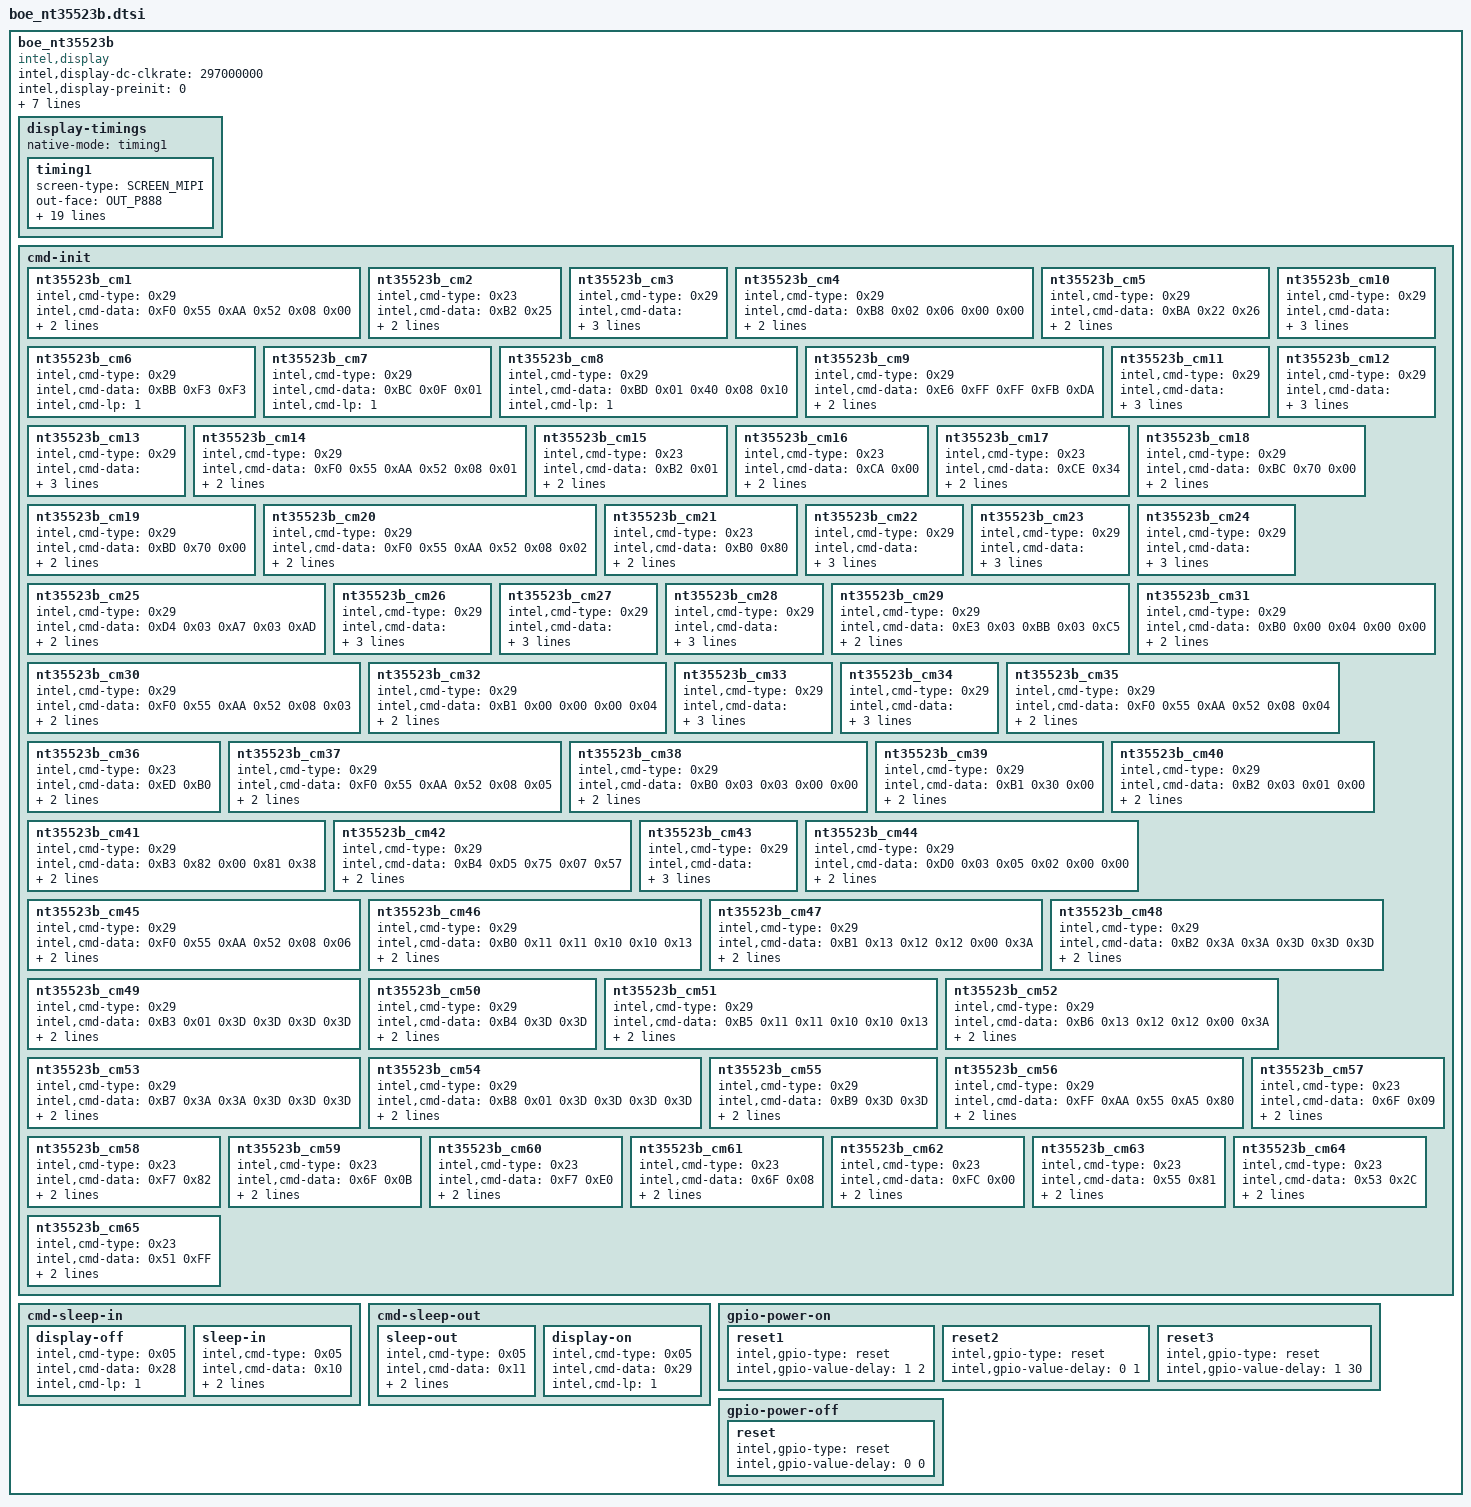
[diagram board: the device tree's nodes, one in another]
/*
 * definition at "include/dt-bindings/sofiafb/sofia_fb.h"
 */
boe_nt35523b {
	compatible = "intel,display";
	intel,display-dc-clkrate = <297000000>;
	intel,display-preinit = <0>;
	intel,display-ramless = <1>;
	intel,display-fps = <60>;
	intel,display-vid-mode = "pulses";
	intel,display-vid-id = <0>;
	intel,display-if-nblanes = <4>;
	intel,display-eot = <0>;
	intel,display-gate = <0>;

        display-timings {
                native-mode = <&timing1>;
                timing1: timing1 {
                        screen-type = <SCREEN_MIPI>;
                        out-face    = <OUT_P888>;
                        color-mode = <COLOR_RGB>;
                        clock-frequency = <71098800>;
                        hactive = <800>;
                        vactive = <1280>;
                        hback-porch = <8>;
                        hfront-porch = <43>;
                        vback-porch = <14>;
                        vfront-porch = <14>;
                        hsync-len = <44>;
                        vsync-len = <4>;
                        hsync-active = <0>;
                        vsync-active = <0>;
                        de-active = <0>;
                        pixelclk-active = <0>;
                        swap-rb = <0>;
                        swap-rg = <0>;
                        swap-gb = <0>;
			width = <95>;
			height = <152>;
                };
        };
	cmd-init{	
			nt35523b_cm1 {
				intel,cmd-type = <0x29>;
				intel,cmd-data = <0xF0 0x55 0xAA 0x52 0x08 0x00>;
				intel,cmd-lp = <1>;
                              intel,cmd-udelay = <20>;
			};
			nt35523b_cm2 {
				intel,cmd-type = <0x23>;
				intel,cmd-data = <0xB2 0x25>;
				intel,cmd-lp = <1>;
                               intel,cmd-udelay = <20>;
			};			
      nt35523b_cm3 {
      intel,cmd-type = <0x29>;
      intel,cmd-data = <0xEF 0x00 0x07 0xFF 0xFF 0x40 0x40>;
      intel,cmd-lp = <1>;
                              intel,cmd-udelay = <20>;
      };
      
			nt35523b_cm4 {
				intel,cmd-type = <0x29>;
				intel,cmd-data = <0xB8 0x02 0x06 0x00 0x00>;
				intel,cmd-lp = <1>;
                                intel,cmd-udelay = <20>;
			};
			nt35523b_cm5 {
				intel,cmd-type = <0x29>;
				intel,cmd-data = <0xBA 0x22 0x26>;
				intel,cmd-lp = <1>;
                                intel,cmd-udelay = <20>;
			};
      nt35523b_cm6 {
      intel,cmd-type = <0x29>;
      intel,cmd-data = <0xBB 0xF3 0xF3>;
                                intel,cmd-lp = <1>;
			};
      nt35523b_cm7 {
      intel,cmd-type = <0x29>;
      intel,cmd-data = <0xBC 0x0F 0x01>;
                                intel,cmd-lp = <1>;
			};
      nt35523b_cm8 {
      intel,cmd-type = <0x29>;
      intel,cmd-data = <0xBD 0x01 0x40 0x08 0x10>;
                                intel,cmd-lp = <1>;
			};						
			nt35523b_cm9 {
				intel,cmd-type = <0x29>;
				intel,cmd-data = <0xE6 0xFF 0xFF 0xFB 0xDA>;
				intel,cmd-lp = <1>;
                                intel,cmd-udelay = <20>;
			};
			nt35523b_cm10 {
				intel,cmd-type = <0x29>;
				intel,cmd-data = <0xCC 0x11 0x11 0x11 0x00 0x00 0x00>;
				intel,cmd-lp = <1>;
                                intel,cmd-udelay = <20>;
			};
			nt35523b_cm11 {
				intel,cmd-type = <0x29>;
				intel,cmd-data = <0xCE 0x10 0x10 0x10 0x10 0x10 0x10 0x10 0x10 0x10 0x10 0x10 0x10>;
				intel,cmd-lp = <1>;
                                intel,cmd-udelay = <20>;
			};
			nt35523b_cm12 {
				intel,cmd-type = <0x29>;
				intel,cmd-data = <0xD7 0x09 0x09 0x09 0x00 0x01 0x00 0x00 0x00 0x01 0x00 0x00 0x00>;
				intel,cmd-lp = <1>;
                                intel,cmd-udelay = <20>;
			};
			nt35523b_cm13 {
				intel,cmd-type = <0x29>;
				intel,cmd-data = <0xD8 0x00 0x00 0x00 0x09 0x09 0x09 0x00 0x00 0x00 0x00 0x09 0x09>;
				intel,cmd-lp = <1>;
                                intel,cmd-udelay = <20>;
			};	
			nt35523b_cm14 {
				intel,cmd-type = <0x29>;
				intel,cmd-data = <0xF0 0x55 0xAA 0x52 0x08 0x01>;
				intel,cmd-lp = <1>;
                                intel,cmd-udelay = <20>;
			};
			nt35523b_cm15 {
				intel,cmd-type = <0x23>;
				intel,cmd-data = <0xB2 0x01>;
				intel,cmd-lp = <1>;
                                intel,cmd-udelay = <20>;
			};
			nt35523b_cm16 {
				intel,cmd-type = <0x23>;
				intel,cmd-data = <0xCA 0x00>;
				intel,cmd-lp = <1>;
                                intel,cmd-udelay = <20>;
			};
			nt35523b_cm17 {
				intel,cmd-type = <0x23>;
				intel,cmd-data = <0xCE 0x34>;
				intel,cmd-lp = <1>;
                                intel,cmd-udelay = <20>;
			};
			nt35523b_cm18 {
				intel,cmd-type = <0x29>;
				intel,cmd-data = <0xBC 0x70 0x00>;
				intel,cmd-lp = <1>;
                                intel,cmd-udelay = <20>;
			};
			nt35523b_cm19 {
				intel,cmd-type = <0x29>;
				intel,cmd-data = <0xBD 0x70 0x00>;
				intel,cmd-lp = <1>;
                                intel,cmd-udelay = <20>;
			};
			nt35523b_cm20 {
				intel,cmd-type = <0x29>;
				intel,cmd-data = <0xF0 0x55 0xAA 0x52 0x08 0x02>;
				intel,cmd-lp = <1>;
                                intel,cmd-udelay = <20>;
			};
			nt35523b_cm21 {
				intel,cmd-type = <0x23>;
				intel,cmd-data = <0xB0 0x80>;
				intel,cmd-lp = <1>;
                                intel,cmd-udelay = <20>;
			};
			nt35523b_cm22 {
				intel,cmd-type = <0x29>;
				intel,cmd-data = <0xD1 0x00 0x24 0x00 0x32 0x00 0x56 0x00 0x6B 0x00 0x89 0x00 0xAA 0x00 0xC7 0x00 0xF3>;
				intel,cmd-lp = <1>;
                                intel,cmd-udelay = <20>;
			};
			nt35523b_cm23 {
				intel,cmd-type = <0x29>;
				intel,cmd-data = <0xD2 0x01 0x18 0x01 0x52 0x01 0x82 0x01 0xC9 0x02 0x05 0x02 0x07 0x02 0x3D 0x02 0x77>;
				intel,cmd-lp = <1>;
                                intel,cmd-udelay = <20>;
			};
			nt35523b_cm24 {
				intel,cmd-type = <0x29>;
				intel,cmd-data = <0xD3 0x02 0x9C 0x02 0xCF 0x02 0xF2 0x03 0x1F 0x03 0x3C 0x03 0x60 0x03 0x75 0x03 0x8E>;
				intel,cmd-lp = <1>;
                                intel,cmd-udelay = <20>;
			};
			nt35523b_cm25 {
				intel,cmd-type = <0x29>;
				intel,cmd-data = <0xD4 0x03 0xA7 0x03 0xAD>;
				intel,cmd-lp = <1>;
                                intel,cmd-udelay = <20>;
			};

			nt35523b_cm26 {
				intel,cmd-type = <0x29>;
				intel,cmd-data = <0xE0 0x00 0x0A 0x00 0x1E 0x00 0x46 0x00 0x5F 0x00 0x7F 0x00 0xA2 0x00 0xC1 0x00 0xEF>;
				intel,cmd-lp = <1>;
                                intel,cmd-udelay = <20>;
			};
			nt35523b_cm27 {
				intel,cmd-type = <0x29>;
				intel,cmd-data = <0xE1 0x01 0x14 0x01 0x50 0x01 0x80 0x01 0xC9 0x02 0x05 0x02 0x07 0x02 0x3D 0x02 0x79>;
				intel,cmd-lp = <1>;
                                intel,cmd-udelay = <20>;
			};
			nt35523b_cm28 {
				intel,cmd-type = <0x29>;
				intel,cmd-data = <0xE2 0x02 0x9E 0x02 0xD3 0x02 0xF6 0x03 0x25 0x03 0x44 0x03 0x6A 0x03 0x81 0x03 0x9E>;
				intel,cmd-lp = <1>;
                                intel,cmd-udelay = <20>;
			};
			nt35523b_cm29 {
				intel,cmd-type = <0x29>;
				intel,cmd-data = <0xE3 0x03 0xBB 0x03 0xC5>;
				intel,cmd-lp = <1>;
                                intel,cmd-udelay = <20>;
			};			
			
			nt35523b_cm30 {
				intel,cmd-type = <0x29>;
				intel,cmd-data = <0xF0 0x55 0xAA 0x52 0x08 0x03>;
				intel,cmd-lp = <1>;
                                intel,cmd-udelay = <20>;
			};
			nt35523b_cm31 {
				intel,cmd-type = <0x29>;
				intel,cmd-data = <0xB0 0x00 0x04 0x00 0x00>;
				intel,cmd-lp = <1>;
                                intel,cmd-udelay = <20>;
			};
			nt35523b_cm32 {
        intel,cmd-type = <0x29>;
        intel,cmd-data = <0xB1 0x00 0x00 0x00 0x04>;
        intel,cmd-lp = <1>;
        intel,cmd-udelay = <20>;
                        };
			nt35523b_cm33 {
				intel,cmd-type = <0x29>;
				intel,cmd-data = <0xB2 0x00 0x00 0x04 0x02 0x00 0xF5 0x42>;
				intel,cmd-lp = <1>;
                                intel,cmd-udelay = <20>;
			};
			nt35523b_cm34 {
				intel,cmd-type = <0x29>;
				intel,cmd-data = <0xBA 0x83 0x01 0x00 0x02 0x00 0xF5 0x42>;
				intel,cmd-lp = <1>;
                                intel,cmd-udelay = <20>;
			};
      nt35523b_cm35 {
        intel,cmd-type = <0x29>;
        intel,cmd-data = <0xF0 0x55 0xAA 0x52 0x08 0x04>;
        intel,cmd-lp = <1>;
                                intel,cmd-udelay = <20>;
      };   
      nt35523b_cm36 {
        intel,cmd-type = <0x23>;
        intel,cmd-data = <0xED 0xB0>;
        intel,cmd-lp = <1>;
                                intel,cmd-udelay = <20>;
      };
        
      nt35523b_cm37 {
        intel,cmd-type = <0x29>;
        intel,cmd-data = <0xF0 0x55 0xAA 0x52 0x08 0x05>;
        intel,cmd-lp = <1>;
                                intel,cmd-udelay = <20>;
      };   
      nt35523b_cm38 {
        intel,cmd-type = <0x29>;
        intel,cmd-data = <0xB0 0x03 0x03 0x00 0x00>;
        intel,cmd-lp = <1>;
                                intel,cmd-udelay = <20>;
      };     
      nt35523b_cm39 {
        intel,cmd-type = <0x29>;
        intel,cmd-data = <0xB1 0x30 0x00>;
        intel,cmd-lp = <1>;
                                intel,cmd-udelay = <20>;
      };   
      nt35523b_cm40 {
        intel,cmd-type = <0x29>;
        intel,cmd-data = <0xB2 0x03 0x01 0x00>;
        intel,cmd-lp = <1>;
                                intel,cmd-udelay = <20>;
      };   
      nt35523b_cm41 {
        intel,cmd-type = <0x29>;
        intel,cmd-data = <0xB3 0x82 0x00 0x81 0x38>;
        intel,cmd-lp = <1>;
                                intel,cmd-udelay = <20>;
      };   
      nt35523b_cm42 {
        intel,cmd-type = <0x29>;
        intel,cmd-data = <0xB4 0xD5 0x75 0x07 0x57>;
        intel,cmd-lp = <1>;
                                intel,cmd-udelay = <20>;
      };                
      nt35523b_cm43 {
        intel,cmd-type = <0x29>;
        intel,cmd-data = <0xB6 0x01 0x00 0xD5 0x71 0x07 0x57>;
        intel,cmd-lp = <1>;
                                intel,cmd-udelay = <20>;
      };   
      nt35523b_cm44 {
        intel,cmd-type = <0x29>;
        intel,cmd-data = <0xD0 0x03 0x05 0x02 0x00 0x00>;
        intel,cmd-lp = <1>;
                                intel,cmd-udelay = <20>;
      };          
			nt35523b_cm45 {
				intel,cmd-type = <0x29>;
				intel,cmd-data = <0xF0 0x55 0xAA 0x52 0x08 0x06>;
				intel,cmd-lp = <1>;
                                intel,cmd-udelay = <20>;
			};
			nt35523b_cm46 {
				intel,cmd-type = <0x29>;
				intel,cmd-data = <0xB0 0x11 0x11 0x10 0x10 0x13>;
				intel,cmd-lp = <1>;
                                intel,cmd-udelay = <20>;
			};
			nt35523b_cm47 {
				intel,cmd-type = <0x29>;
				intel,cmd-data = <0xB1 0x13 0x12 0x12 0x00 0x3A>;
				intel,cmd-lp = <1>;
                                intel,cmd-udelay = <20>;
			};
			nt35523b_cm48 {
				intel,cmd-type = <0x29>;
				intel,cmd-data = <0xB2 0x3A 0x3A 0x3D 0x3D 0x3D>;
				intel,cmd-lp = <1>;
                                intel,cmd-udelay = <20>;
			};
			nt35523b_cm49 {
				intel,cmd-type = <0x29>;
				intel,cmd-data = <0xB3 0x01 0x3D 0x3D 0x3D 0x3D>;
				intel,cmd-lp = <1>;
                                intel,cmd-udelay = <20>;
			};
			nt35523b_cm50 {
				intel,cmd-type = <0x29>;
				intel,cmd-data = <0xB4 0x3D 0x3D>;
				intel,cmd-lp = <1>;
                                intel,cmd-udelay = <20>;
			};
			nt35523b_cm51 {
				intel,cmd-type = <0x29>;
				intel,cmd-data = <0xB5 0x11 0x11 0x10 0x10 0x13>;
				intel,cmd-lp = <1>;
                                intel,cmd-udelay = <20>;
			};

			nt35523b_cm52 {
				intel,cmd-type = <0x29>;
				intel,cmd-data = <0xB6 0x13 0x12 0x12 0x00 0x3A>;
				intel,cmd-lp = <1>;
                                intel,cmd-udelay = <20>;
			};
			nt35523b_cm53 {
				intel,cmd-type = <0x29>;
				intel,cmd-data = <0xB7 0x3A 0x3A 0x3D 0x3D 0x3D>;
				intel,cmd-lp = <1>;
                                intel,cmd-udelay = <20>;
			};
			nt35523b_cm54 {
				intel,cmd-type = <0x29>;
				intel,cmd-data = <0xB8 0x01 0x3D 0x3D 0x3D 0x3D>;
				intel,cmd-lp = <1>;
                                intel,cmd-udelay = <20>;
			};
			nt35523b_cm55 {
				intel,cmd-type = <0x29>;
				intel,cmd-data = <0xB9 0x3D 0x3D>;
				intel,cmd-lp = <1>;
                                intel,cmd-udelay = <20>;
			};			
			nt35523b_cm56 {
				intel,cmd-type = <0x29>;
				intel,cmd-data = <0xFF 0xAA 0x55 0xA5 0x80>;
				intel,cmd-lp = <1>;
                                intel,cmd-udelay = <20>;
			};
			nt35523b_cm57 {
				intel,cmd-type = <0x23>;
				intel,cmd-data = <0x6F 0x09>;
				intel,cmd-lp = <1>;
                                intel,cmd-udelay = <20>;
			};
			nt35523b_cm58 {
				intel,cmd-type = <0x23>;
				intel,cmd-data = <0xF7 0x82>;
				intel,cmd-lp = <1>;
                                intel,cmd-udelay = <20>;
			};
			nt35523b_cm59 {
				intel,cmd-type = <0x23>;
				intel,cmd-data = <0x6F 0x0B>;
				intel,cmd-lp = <1>;
                                intel,cmd-udelay = <20>;
			};

			nt35523b_cm60 {
				intel,cmd-type = <0x23>;
				intel,cmd-data = <0xF7 0xE0>;
				intel,cmd-lp = <1>;
                                intel,cmd-udelay = <20>;
			};						
			nt35523b_cm61 {
				intel,cmd-type = <0x23>;
				intel,cmd-data = <0x6F 0x08>;
				intel,cmd-lp = <1>;
                                intel,cmd-udelay = <20>;
			};

			nt35523b_cm62 {
				intel,cmd-type = <0x23>;
				intel,cmd-data = <0xFC 0x00>;
				intel,cmd-lp = <1>;
                                intel,cmd-udelay = <20>;
			};			
			nt35523b_cm63 {
				intel,cmd-type = <0x23>;
				intel,cmd-data = <0x55 0x81>;
				intel,cmd-lp = <1>;
                                intel,cmd-udelay = <20>;
			};
			nt35523b_cm64 {
				intel,cmd-type = <0x23>;
				intel,cmd-data = <0x53 0x2C>;
				intel,cmd-lp = <1>;
                                intel,cmd-udelay = <20>;
			};
			nt35523b_cm65 {
				intel,cmd-type = <0x23>;
				intel,cmd-data = <0x51 0xFF>;
				intel,cmd-lp = <1>;
                                intel,cmd-udelay = <20>;
			};
	};

	cmd-sleep-in {
		display-off{
			intel,cmd-type = <0x05>;
			intel,cmd-data = <0x28>;
			intel,cmd-lp = <1>;
		};
		sleep-in{
			intel,cmd-type = <0x05>;
			intel,cmd-data = <0x10>;
			intel,cmd-delay = <20>;
			intel,cmd-lp = <1>;
		};
	};

	cmd-sleep-out {
		sleep-out{
			intel,cmd-type = <0x05>;
			intel,cmd-data = <0x11>;
			intel,cmd-delay = <120>;
			intel,cmd-lp = <1>;
		};
		display-on{
			intel,cmd-type = <0x05>;
			intel,cmd-data = <0x29>;
			intel,cmd-lp = <1>;
		};
	};

       gpio-power-on {
               reset1 {
                       intel,gpio-type = "reset";
                       intel,gpio-value-delay = <1 2>;
               };
               reset2 {
                       intel,gpio-type = "reset";
                       intel,gpio-value-delay = <0 1>;
               };
               reset3 {
                       intel,gpio-type = "reset";
                       intel,gpio-value-delay = <1 30>;
               };
       };

       gpio-power-off {
               reset {
                       intel,gpio-type = "reset";
                       intel,gpio-value-delay = <0 0>;
               };
       };

};
